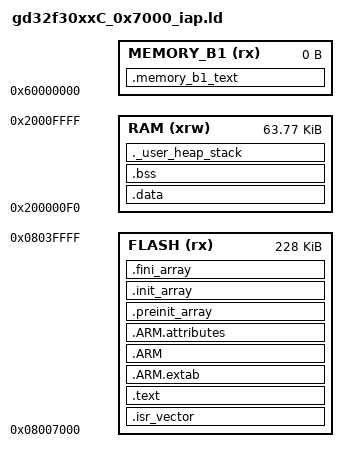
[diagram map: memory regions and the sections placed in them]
/*
 *
 * Automatically generated file
 * PlatformIO default linker script template for STM32 F1/F2/F3/F4/F7/L0/L1/L4
 *
 */

/* Entry Point */
ENTRY(Reset_Handler)

/* Generate a link error if heap and stack don't fit into RAM */
_Min_Heap_Size = 0x5000;     /* required amount of heap  */
_Min_Stack_Size = 0x2000;    /* required amount of stack */

/* Specify the memory areas */
/*
 * NOTE 1: RAM ORIGIN is offset by 0xF0 from 0x20000000 because the MKS GD32F305
 * bootloader corrupts the first ~240 bytes of SRAM when it jumps to the app
 * (documented by kisslorand in BTT-TFT-FW README).
 *
 * NOTE 2: RAM is 96K on GD32F305VCT6. _estack is set to 0x20017FF0 (16 bytes
 * below top of RAM 0x20018000), exactly matching the working reference binary.
 * When the Artillery v3.0.5 bootloader jumps to app, it pops 8 bytes from MSP,
 * moving MSP to 0x20017FF8 safely within physical SRAM.
 */
MEMORY
{
  FLASH (rx)      : ORIGIN = 0x08007000, LENGTH = 256K - 28K
  RAM (xrw)       : ORIGIN = 0x200000F0, LENGTH = 64K - 0xF0
  MEMORY_B1 (rx)  : ORIGIN = 0x60000000, LENGTH = 0K
}

/* Highest address of the user mode stack */
_estack = 0x20010000;

/* Define output sections */
SECTIONS
{
  /* The startup code goes first into FLASH */
  .isr_vector :
  {
    . = ALIGN(4);
    KEEP(*(.isr_vector)) /* Startup code */
    . = ALIGN(4);
  } >FLASH

  /* The program code and other data goes into FLASH */
  .text :
  {
    . = ALIGN(4);
    *(.text)           /* .text sections (code) */
    *(.text*)          /* .text* sections (code) */
    *(.rodata)         /* .rodata sections (constants, strings, etc.) */
    *(.rodata*)        /* .rodata* sections (constants, strings, etc.) */
    *(.glue_7)         /* glue arm to thumb code */
    *(.glue_7t)        /* glue thumb to arm code */

    KEEP (*(.init))
    KEEP (*(.fini))

    . = ALIGN(4);
    _etext = .;        /* define a global symbols at end of code */
  } >FLASH

  .ARM.extab   : { *(.ARM.extab* .gnu.linkonce.armextab.*) } >FLASH
  .ARM : {
    __exidx_start = .;
    *(.ARM.exidx*)
    __exidx_end = .;
  } >FLASH

  .ARM.attributes : { *(.ARM.attributes) } > FLASH

  .preinit_array     :
  {
    PROVIDE_HIDDEN (__preinit_array_start = .);
    KEEP (*(.preinit_array*))
    PROVIDE_HIDDEN (__preinit_array_end = .);
  } >FLASH
  .init_array :
  {
    PROVIDE_HIDDEN (__init_array_start = .);
    KEEP (*(SORT(.init_array.*)))
    KEEP (*(.init_array*))
    PROVIDE_HIDDEN (__init_array_end = .);
  } >FLASH
  .fini_array :
  {
    PROVIDE_HIDDEN (__fini_array_start = .);
    KEEP (*(SORT(.fini_array.*)))
    KEEP (*(.fini_array*))
    PROVIDE_HIDDEN (__fini_array_end = .);
  } >FLASH

  /* used by the startup to initialize data */
  _sidata = .;

  /* Initialized data sections goes into RAM, load LMA copy after code */
  .data : AT ( _sidata )
  {
    . = ALIGN(4);
    _sdata = .;        /* create a global symbol at data start */
    *(.data)           /* .data sections */
    *(.data*)          /* .data* sections */

    . = ALIGN(4);
    _edata = .;        /* define a global symbol at data end */
  } >RAM

  /* Uninitialized data section */
  . = ALIGN(4);
  .bss :
  {
    /* This is used by the startup in order to initialize the .bss secion */
    _sbss = .;         /* define a global symbol at bss start */
    __bss_start__ = _sbss;
    *(.bss)
    *(.bss*)
    *(COMMON)

    . = ALIGN(4);
    _ebss = .;         /* define a global symbol at bss end */
    __bss_end__ = _ebss;
  } >RAM

  PROVIDE ( end = _ebss );
  PROVIDE ( _end = _ebss );

  /* User_heap_stack section, used to check that there is enough RAM left */
  ._user_heap_stack :
  {
    . = ALIGN(4);
    . = . + _Min_Heap_Size;
    . = . + _Min_Stack_Size;
    . = ALIGN(4);
  } >RAM

  /* MEMORY_bank1 section, code must be located here explicitly            */
  /* Example: extern int foo(void) __attribute__ ((section (".mb1text"))); */
  .memory_b1_text :
  {
    *(.mb1text)        /* .mb1text sections (code) */
    *(.mb1text*)       /* .mb1text* sections (code)  */
    *(.mb1rodata)      /* read-only data (constants) */
    *(.mb1rodata*)
  } >MEMORY_B1

  /* Remove information from the standard libraries */
  /DISCARD/ :
  {
    libc.a ( * )
    libm.a ( * )
    libgcc.a ( * )
  }
}
